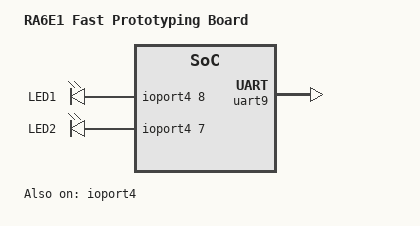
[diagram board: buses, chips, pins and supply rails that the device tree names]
/*
 * Copyright (c) 2023 TOKITA Hiroshi <tokita.hiroshi@fujitsu.com>
 *
 * SPDX-License-Identifier: Apache-2.0
 */

/dts-v1/;
#include <renesas/ra/ra6e1/r7fa6e10f2cfp.dtsi>
#include "fpb_ra6e1-pinctrl.dtsi"

/ {
	model = "RA6E1 Fast Prototyping Board";
	compatible = "renesas,r7fa6e10f2cfp";

	chosen {
		zephyr,console = &uart9;
		zephyr,shell-uart = &uart9;
		zephyr,sram = &sram0;
		zephyr,flash = &flash0;
	};

	leds {
		compatible = "gpio-leds";
		led1: led1 {
			gpios = <&ioport4 8 GPIO_ACTIVE_HIGH>;
			label = "LED1";
		};

		led2: led2 {
			gpios = <&ioport4 7 GPIO_ACTIVE_HIGH>;
			label = "LED2";
		};
	};

	aliases {
		led0 = &led1;
	};
};

&uart9 {
	status = "okay";
        pinctrl-0 = <&uart9_default>;
        pinctrl-names = "default";
};

&ioport4 {
	status = "okay";
};
